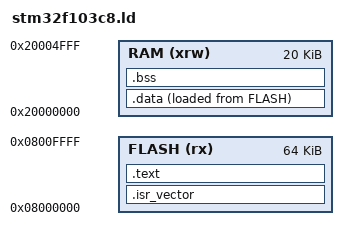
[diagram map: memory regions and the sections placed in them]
MEMORY
{
  FLASH (rx) : ORIGIN = 0x08000000, LENGTH = 64K
  RAM (xrw)  : ORIGIN = 0x20000000, LENGTH = 20K
}

_estack = ORIGIN(RAM) + LENGTH(RAM);

SECTIONS
{
  .isr_vector :
  {
    KEEP(*(.isr_vector))
  } > FLASH

  .text :
  {
    *(.text*)
    *(.rodata*)
    *(.glue_7)
    *(.glue_7t)
    _etext = .;
  } > FLASH

  _sidata = LOADADDR(.data);

  .data :
  {
    _sdata = .;
    *(.data*)
    _edata = .;
  } > RAM AT > FLASH

  .bss :
  {
    _sbss = .;
    *(.bss*)
    *(COMMON)
    _ebss = .;
  } > RAM

  /DISCARD/ :
  {
    *(.note*)
    *(.comment*)
  }
}
